# STM32C5A3xx register map
File version: 1.0
Registers are 32-bit, read-write, reset 0x0 unless marked. A register's access mark holds for its fields unless they carry their own. Offsets are from the block's base; [hi:lo] are bit positions; {n}, {i} and the like mark numbered series.

## PWR — Power Control (PWR)
Base 0x44020800
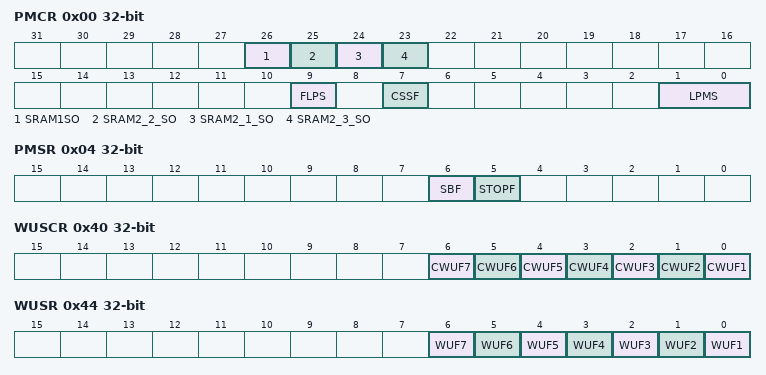
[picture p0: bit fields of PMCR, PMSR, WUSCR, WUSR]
0x00 PMCR — PWR power mode control register
  [26] SRAM1SO
  [25] SRAM2_2_SO
  [24] SRAM2_1_SO
  [23] SRAM2_3_SO
  [9] FLPS
  [7] CSSF
  [1:0] LPMS — low-power mode selection
0x04 PMSR ro — PWR status register
  [6] SBF — System standby flag
  [5] STOPF — Stop flag
0x24 RTCCR — PWR RTC domain control register
  [0] DRTCP — Disable RTC domain write protection
0x34 VMCR — PWR voltage monitor control register
  [0] PVDE — PVD enable
0x3C VMSR ro — PWR voltage monitor status register
  [22] PVDO — programmable voltage detect output
0x40 WUSCR — PWR wake-up status clear register
  [n-1] CWUF{n} (n=1..7)
0x44 WUSR ro — PWR wake-up status register
  [n-1] WUF{n} (n=1..7) — wake-up pin WUFx flag
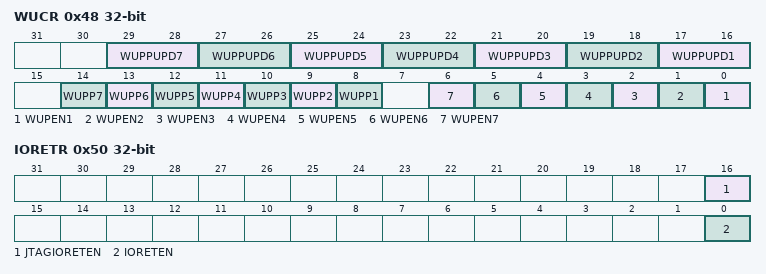
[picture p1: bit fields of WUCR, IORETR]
0x48 WUCR — PWR wake-up configuration register
  [2n+15:2n+14] WUPPUPD{n} (n=1..7)
  [n+7] WUPP{n} (n=1..7)
  [n-1] WUPEN{n} (n=1..7) — Enable wake-up pin WKUPx (x = 7 to 1)
0x50 IORETR — PWR I/O retention register
  [16] JTAGIORETEN — IO retention enable for JTAG I/Os
  [0] IORETEN — IO retention enable
0x104 PRIVCFGR — PWR privilege configuration register
  [1] PRIV

## EXTI — Extended interrupts and event controller (EXTI)
Base 0x44022000
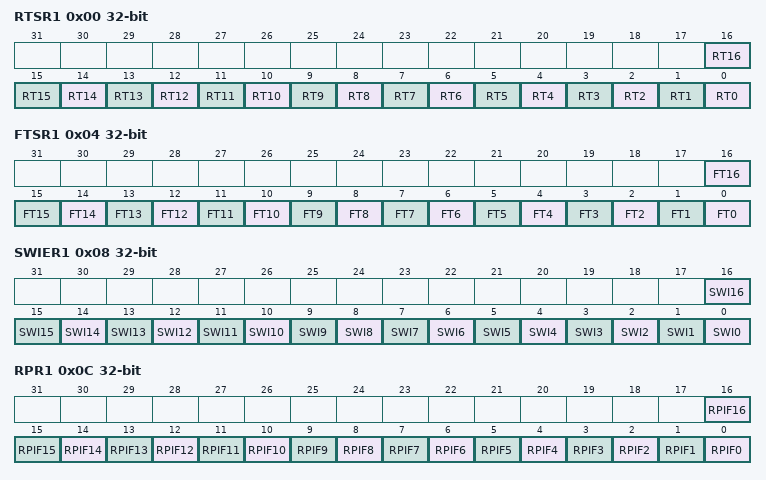
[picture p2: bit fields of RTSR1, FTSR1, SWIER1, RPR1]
0x00 RTSR1 — EXTI Rising Trigger Selection Register 1
  [n] RT{n} (n=0..16)
0x04 FTSR1 — EXTI Falling Trigger Selection Register 1
  [n] FT{n} (n=0..16)
0x08 SWIER1 — EXTI Software Interrupt event Register 1
  [n] SWI{n} (n=0..16) — Software interrupt on event {n}
0x0C RPR1 — EXTI Rising Pending Register 1
  [n] RPIF{n} (n=0..16)
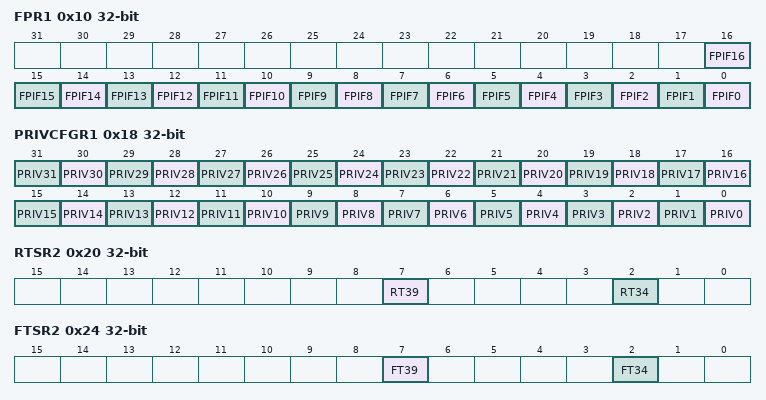
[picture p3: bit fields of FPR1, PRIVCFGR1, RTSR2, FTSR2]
0x10 FPR1 — EXTI Falling Pending Register 1
  [n] FPIF{n} (n=0..16)
0x18 PRIVCFGR1 — EXTI Privilege Configuration Register 1
  [n] PRIV{n} (n=0..31) — Privilege enable on event input {n}
0x20 RTSR2 — EXTI Rising Trigger Selection Register 2
  [7] RT39, [2] RT34
0x24 FTSR2 — EXTI Falling Trigger Selection Register 2
  [7] FT39, [2] FT34
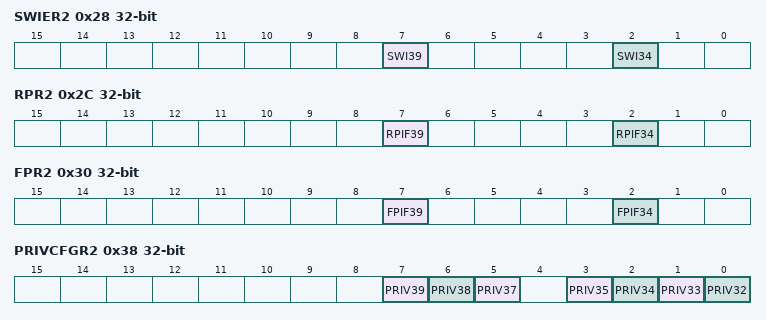
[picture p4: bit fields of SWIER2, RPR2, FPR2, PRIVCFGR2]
0x28 SWIER2 — EXTI Software Interrupt event Register 2
  [7] SWI39 — Software Interrupt on event 39
  [2] SWI34 — Software Interrupt on event 34
0x2C RPR2 — EXTI Rising Pending Register 2
  [7] RPIF39, [2] RPIF34
0x30 FPR2 — EXTI Falling Pending Register 2
  [7] FPIF39, [2] FPIF34
0x38 PRIVCFGR2 — EXTI Privilege Configuration Register 2
  [7] PRIV39 — Privilege enable on event input 39
  [6] PRIV38 — Privilege enable on event input 38
  [5] PRIV37 — Privilege enable on event input 37
  [n-32] PRIV{n} (n=32..35) — Privilege enable on event input {n}
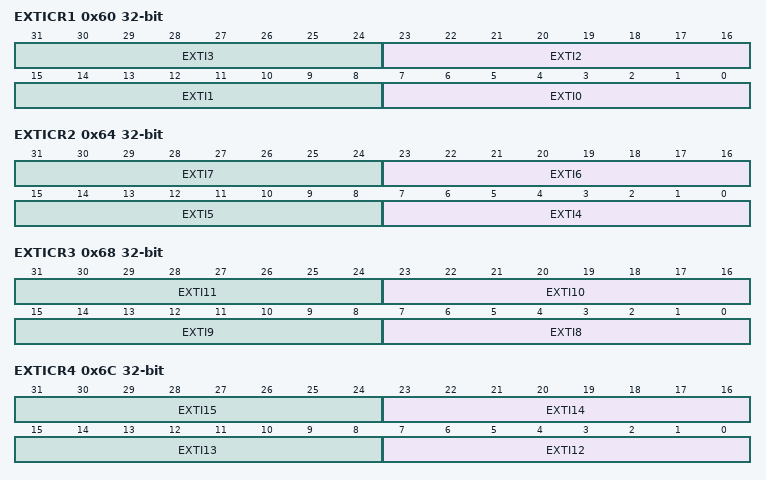
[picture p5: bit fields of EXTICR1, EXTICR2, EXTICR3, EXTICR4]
0x60 EXTICR1 — EXIT External Interrupt Configuration Register
  [8n+7:8n] EXTI{n} (n=0..3) — EXTI{n} GPIO port selection
0x64 EXTICR2 — EXIT External Interrupt Configuration Register
  [8n-25:8n-32] EXTI{n} (n=4..7) — EXTI{n} GPIO port selection
0x68 EXTICR3 — EXIT External Interrupt Configuration Register
  [8n-57:8n-64] EXTI{n} (n=8..11) — EXTI{n} GPIO port selection
0x6C EXTICR4 — EXIT External Interrupt Configuration Register
  [8n-89:8n-96] EXTI{n} (n=12..15) — EXTI{n} GPIO port selection
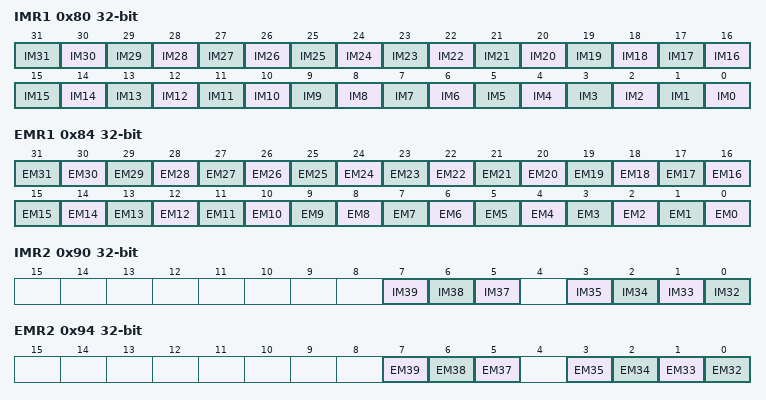
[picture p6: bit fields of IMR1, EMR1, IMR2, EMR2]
0x80 IMR1 — EXTI Interrupt Mask Register 1
  [n] IM{n} (n=0..31)
0x84 EMR1 — EXTI Event Mask Register 1
  [n] EM{n} (n=0..31)
0x90 IMR2 — EXTI Interrupt Mask Register 2
  [7] IM39, [6] IM38, [5] IM37, [n-32] IM{n} (n=32..35)
0x94 EMR2 — EXTI Event Mask Register 2
  [7] EM39, [6] EM38, [5] EM37, [n-32] EM{n} (n=32..35)

## DBGMCU — Debug MCU (DBGMCU)
Base 0x44024000
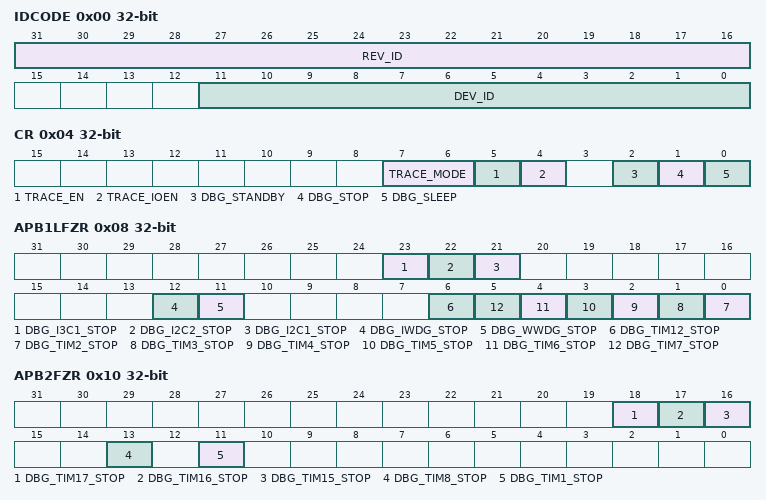
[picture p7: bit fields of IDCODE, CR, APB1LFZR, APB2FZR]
0x00 IDCODE ro — DBGMCU identity code register
  [31:16] REV_ID, [11:0] DEV_ID
0x04 CR — DBGMCU configuration register
  [7:6] TRACE_MODE, [5] TRACE_EN, [4] TRACE_IOEN, [2] DBG_STANDBY, [1] DBG_STOP, [0] DBG_SLEEP
0x08 APB1LFZR — DBGMCU APB1L peripheral freeze register
  [23] DBG_I3C1_STOP, [22] DBG_I2C2_STOP, [21] DBG_I2C1_STOP, [12] DBG_IWDG_STOP, [11] DBG_WWDG_STOP, [6] DBG_TIM12_STOP, [n-2] DBG_TIM{n}_STOP (n=2..7)
0x0C APB1HFZR — Debug MCU APB1 freeze register 2
0x10 APB2FZR — DBGMCU APB2 peripheral freeze register
  [18] DBG_TIM17_STOP, [17] DBG_TIM16_STOP, [16] DBG_TIM15_STOP, [13] DBG_TIM8_STOP, [11] DBG_TIM1_STOP
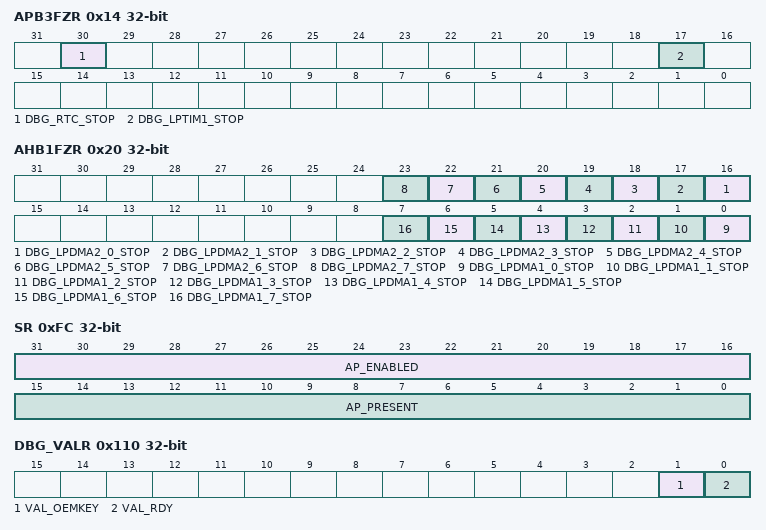
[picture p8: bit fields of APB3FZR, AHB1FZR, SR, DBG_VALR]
0x14 APB3FZR — DBGMCU APB3 peripheral freeze register
  [30] DBG_RTC_STOP, [17] DBG_LPTIM1_STOP
0x20 AHB1FZR — DBGMCU AHB1 peripheral freeze register
  [n+16] DBG_LPDMA2_{n}_STOP (n=0..7), [n] DBG_LPDMA1_{n}_STOP (n=0..7)
0xFC SR — DBGMCU status register
  [31:16] AP_ENABLED, [15:0] AP_PRESENT
0x100 DBG_AUTH_HOST — DBGMCU debug authentication mailbox host register
  [31:0] AUTH_KEY
0x104 DBG_AUTH_DEVICE ro — DBGMCU debug authentication mailbox device register
  [31:0] AUTH_ID
0x10C DBG_BSKEY_PWD — DBGMCU boundary-scan key password register
0x110 DBG_VALR ro — DBGMCU debug OEMKEY validation register
  [1] VAL_OEMKEY, [0] VAL_RDY
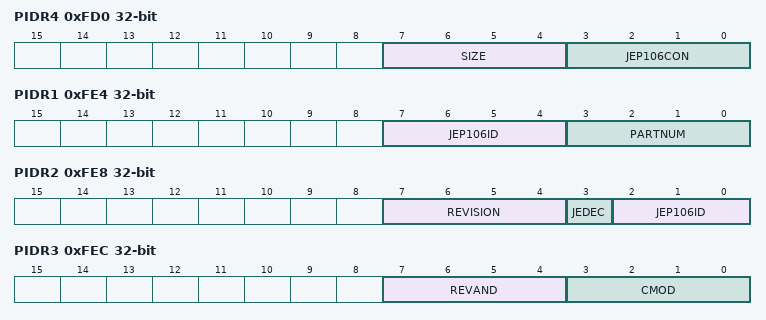
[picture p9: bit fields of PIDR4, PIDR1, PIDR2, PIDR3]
0xFD0 PIDR4 ro — DBGMCU CoreSight peripheral identity register 4
  [7:4] SIZE, [3:0] JEP106CON
0xFE0 PIDR0 ro — DBGMCU CoreSight peripheral identity register 0
  [7:0] PARTNUM
0xFE4 PIDR1 ro — DBGMCU CoreSight peripheral identity register 1
  [7:4] JEP106ID, [3:0] PARTNUM
0xFE8 PIDR2 ro — DBGMCU CoreSight peripheral identity register 2
  [7:4] REVISION, [3] JEDEC, [2:0] JEP106ID
0xFEC PIDR3 ro — DBGMCU CoreSight peripheral identity register 3
  [7:4] REVAND, [3:0] CMOD
0xFF0 CIDR0 ro — DBGMCU CoreSight component identity register 0
  [7:0] PREAMBLE
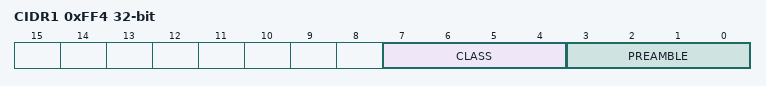
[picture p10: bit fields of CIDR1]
0xFF4 CIDR1 ro — DBGMCU CoreSight component identity register 1
  [7:4] CLASS, [3:0] PREAMBLE
0xFF8 CIDR2 ro — DBGMCU CoreSight component identity register 2
  [7:0] PREAMBLE
0xFFC CIDR3 ro — DBGMCU CoreSight component identity register 3
  [7:0] PREAMBLE

## DLYB_XSPI1 — Delay block (DLYB)
Base 0x4600F000
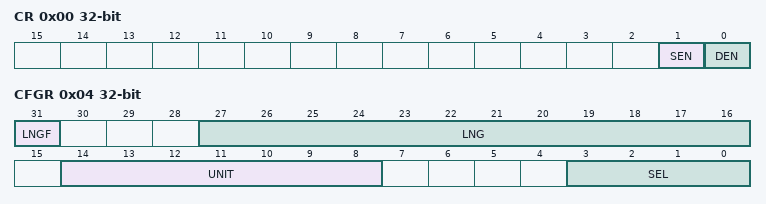
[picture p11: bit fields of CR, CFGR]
0x00 CR — DLYB control register
  [1] SEN — Sampler length enable bit
  [0] DEN — Delay block enable bit
0x04 CFGR — DLYB configuration register
  [31] LNGF — Length valid flag
  [27:16] LNG — Delay line length value
  [14:8] UNIT — Delay of a unit delay cell
  [3:0] SEL — Phase for the output clock
